# GD32F20x_CL register map
File version: 1.0
CPU: CM3 r2p1, little endian, no MPU, no FPU, 4 interrupt priority bits
Registers are 32-bit, read-write, reset 0x0 unless marked. A register's access mark holds for its fields unless they carry their own. Offsets are from the block's base; [hi:lo] are bit positions; {n}, {i} and the like mark numbered series.

## DBG — Debug support
Base 0xE0042000
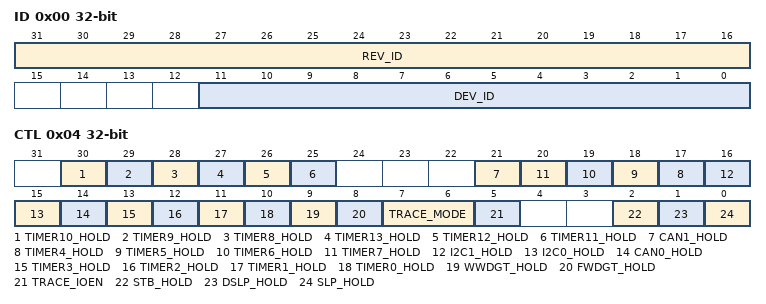
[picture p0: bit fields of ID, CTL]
0x00 ID ro — ID code register
  [31:16] REV_ID — REV ID code register
  [11:0] DEV_ID — DEV ID code register
0x04 CTL — Control register
  [30] TIMER10_HOLD — TIMER 10 hold bit
  [29] TIMER9_HOLD — TIMER 9 hold bit
  [28] TIMER8_HOLD — TIMER 8 hold bit
  [27] TIMER13_HOLD — TIMER 13 hold bit
  [26] TIMER12_HOLD — TIMER 12 hold bit
  [25] TIMER11_HOLD — TIMER 11 hold bit
  [21] CAN1_HOLD — CAN1 hold bit
  [n+13] TIMER{n}_HOLD (n=4..7) — TIMER {n} hold bit
  [16] I2C1_HOLD — I2C1 hold bit
  [15] I2C0_HOLD — I2C0 hold bit
  [14] CAN0_HOLD — CAN0 hold bit
  [13] TIMER3_HOLD — TIMER 23 hold bit
  [12] TIMER2_HOLD — TIMER 2 hold bit
  [11] TIMER1_HOLD — TIMER 1 hold bit
  [10] TIMER0_HOLD — TIMER 0 hold bit
  [9] WWDGT_HOLD — WWDGT hold bit
  [8] FWDGT_HOLD — FWDGT hold bit
  [7:6] TRACE_MODE — Trace pin allocation mode
  [5] TRACE_IOEN — Trace pin allocation enable
  [2] STB_HOLD — Standby mode hold register
  [1] DSLP_HOLD — Deep-sleep mode hold register
  [0] SLP_HOLD — Sleep mode hold register

## DCI — Digital Camera Interface
Base 0x50050000
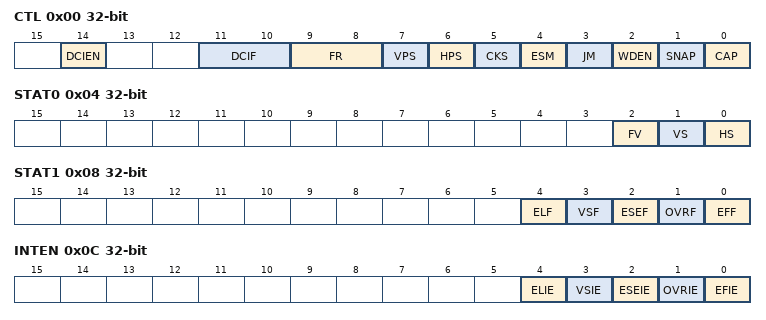
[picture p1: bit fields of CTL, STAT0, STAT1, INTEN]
0x00 CTL — DCI Control register
  [14] DCIEN — DCI Enable
  [11:10] DCIF — Digital camera interface format
  [9:8] FR — Frame rate
  [7] VPS — Vertical Polarity Selection
  [6] HPS — Horizontal Polarity Selection
  [5] CKS — Clock Polarity Selection
  [4] ESM — Embedded synchronous mode
  [3] JM — JPEG mode
  [2] WDEN — Window Enable
  [1] SNAP — Snapshot mode
  [0] CAP — Capture Enable
0x04 STAT0 ro — DCI Status register 0
  [2] FV — FIFO Valid
  [1] VS — VS line status
  [0] HS — HS line status
0x08 STAT1 ro — DCI Status register1
  [4] ELF — End of line flag
  [3] VSF — Vsync Flag
  [2] ESEF — Embedded Synchronous Error Flag
  [1] OVRF — FIFO Overrun flag
  [0] EFF — End of Frame Flag
0x0C INTEN — DCI inrerrupt enable register
  [4] ELIE — End of line interrupt Enable
  [3] VSIE — Vsync Interrupt Enable
  [2] ESEIE — Embedded Synchronous Error Interrupt Enable
  [1] OVRIE — FIFO Overrun interrupt Enable
  [0] EFIE — End of Frame Interrupt Enable
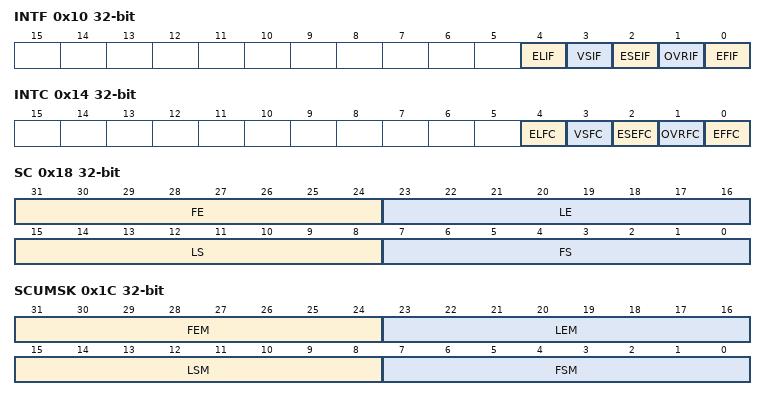
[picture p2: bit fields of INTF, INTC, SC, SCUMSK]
0x10 INTF ro — DCI Interrupt flag register
  [4] ELIF — End of Line Interrupt Flag
  [3] VSIF — Vsync Interrupt Flag
  [2] ESEIF — Embedded Synchronous Error Interrupt Flag
  [1] OVRIF — FIFO Overrun Interrupt Flag
  [0] EFIF — End of Frame Interrupt Flag
0x14 INTC wo — DCI Interrupt flag clear register
  [4] ELFC — End of Line Flag Clear
  [3] VSFC — Vsync flag clear
  [2] ESEFC — Clear embedded synchronous Error Flag
  [1] OVRFC — Clear FIFO Overrun Flag
  [0] EFFC — Clear End of Frame Flag
0x18 SC — DCI Synchronization codes register
  [31:24] FE — Frame end code in embedded synchronous mode
  [23:16] LE — Line end code in embedded synchronous mode
  [15:8] LS — Line start code in embedded synchronous mode
  [7:0] FS — Frame start code in embedded synchronous mode
0x1C SCUMSK — DCI Synchronization codes unmask register
  [31:24] FEM — Frame end code mask bits in embedded synchronous mode
  [23:16] LEM — Line end code mask bits in embedded synchronous mode
  [15:8] LSM — Line start code mask bits in embedded synchronous mode
  [7:0] FSM — Frame start code mask bits in embedded synchronous mode
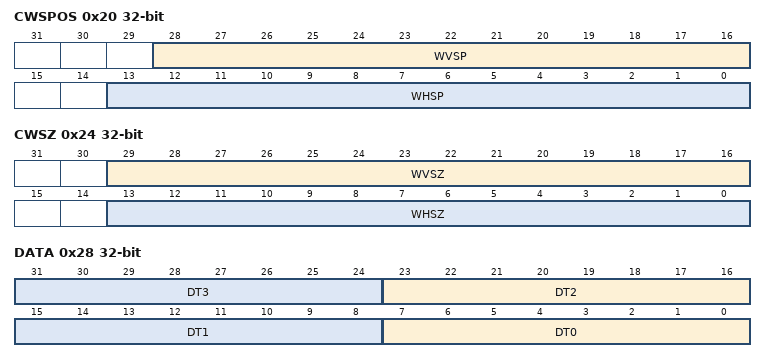
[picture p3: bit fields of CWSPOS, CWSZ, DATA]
0x20 CWSPOS — DCI Cropping window start position register
  [28:16] WVSP — Window Vertical start position
  [13:0] WHSP — Window horizontal start position
0x24 CWSZ — DCI Cropping window size register
  [29:16] WVSZ — Window Vertical Size
  [13:0] WHSZ — Window horizontal Size
0x28 DATA ro — DCI DATA register
  [8n+7:8n] DT{n} (n=0..3) — Pixel Data {n}

## DMA0 — DMA controller
Base 0x40020000
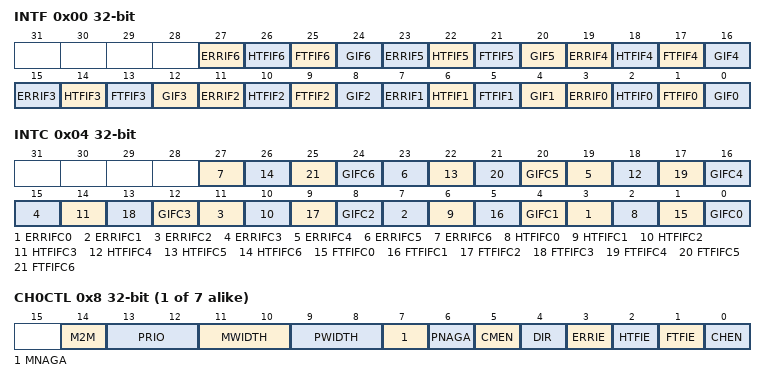
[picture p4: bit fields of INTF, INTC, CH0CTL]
0x00 INTF ro — Interrupt flag register
  [4n+3] ERRIF{n} (n=0..6) — Error flag of channel {n}
  [4n+2] HTFIF{n} (n=0..6) — Half transfer finish flag of channel {n}
  [4n+1] FTFIF{n} (n=0..6) — Full Transfer finish flag of channe {n}
  [4n] GIF{n} (n=0..6) — Global interrupt flag of channel {n}
0x04 INTC wo — Interrupt flag clear register
  [4n+3] ERRIFC{n} (n=0..6) — Clear bit for error flag of channel {n}
  [4n+2] HTFIFC{n} (n=0..6) — Clear bit for half transfer finish flag of channel {n}
  [4n+1] FTFIFC{n} (n=0..6) — Clear bit for full transfer finish flag of channel {n}
  [4n] GIFC{n} (n=0..6) — Clear global interrupt flag of channel {n}
{0x8+0x14*i} CH{i}CTL (i=0..6) — Channel {i} control register
  [14] M2M — Memory to Memory Mode
  [13:12] PRIO — Priority level
  [11:10] MWIDTH — Transfer data size of memory
  [9:8] PWIDTH — Transfer data size of peripheral
  [7] MNAGA — Next address generation algorithm of memory
  [6] PNAGA — Next address generation algorithm of peripheral
  [5] CMEN — Circular mode enable
  [4] DIR — Transfer direction
  [3] ERRIE — Enable bit for channel error interrupt
  [2] HTFIE — Enable bit for channel half transfer finish interrupt
  [1] FTFIE — Enable bit for channel full transfer finish interrupt
  [0] CHEN — Channel enable
{0xC+0x14*i} CH{i}CNT (i=0..6) — Channel {i} counter register
  [15:0] CNT — Transfer counter
{0x10+0x14*i} CH{i}PADDR (i=0..6) — Channel {i} peripheral base address register
  [31:0] PADDR — Peripheral base address
{0x14+0x14*i} CH{i}MADDR (i=0..6) — Channel {i} memory base address register
  [31:0] MADDR — Memory base address

## DMA1 — DMA controller
Base 0x40020400
Registers as DMA0; these are added or differ:
0x300 ACFG — DMA additional configuration register
  [5] FD_CH5EN — Enable bit for channel 5 Full_Data transfer mode
